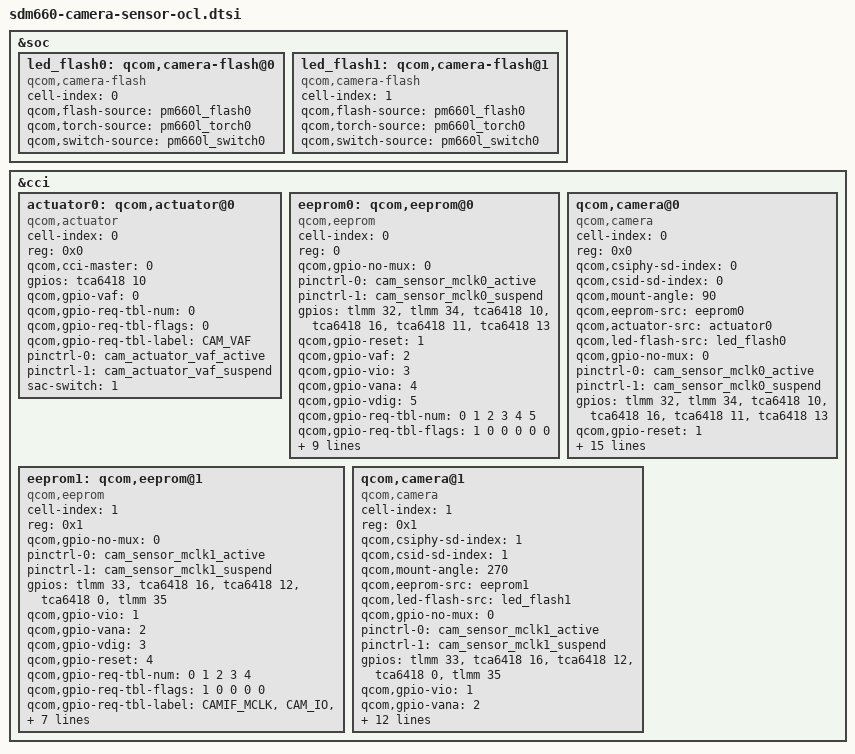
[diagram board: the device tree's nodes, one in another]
/*
 * Copyright (c) 2014, The Linux Foundation. All rights reserved.
 *
 * This program is free software; you can redistribute it and/or modify
 * it under the terms of the GNU General Public License version 2 and
 * only version 2 as published by the Free Software Foundation.
 *
 * This program is distributed in the hope that it will be useful,
 * but WITHOUT ANY WARRANTY; without even the implied warranty of
 * MERCHANTABILITY or FITNESS FOR A PARTICULAR PURPOSE.  See the
 * GNU General Public License for more details.
 */

&soc {
	led_flash0: qcom,camera-flash@0 {
		cell-index = <0>;
		compatible = "qcom,camera-flash";
		qcom,flash-source = <&pm660l_flash0>;
		qcom,torch-source = <&pm660l_torch0>;
		qcom,switch-source = <&pm660l_switch0>;
		status = "ok";
	};
	led_flash1: qcom,camera-flash@1 {
		cell-index = <1>;
		compatible = "qcom,camera-flash";
		qcom,flash-source = <&pm660l_flash0>;
		qcom,torch-source = <&pm660l_torch0>;
		qcom,switch-source = <&pm660l_switch0>;
		status = "ok";
	};
};

&cci {
	actuator0: qcom,actuator@0 {
		cell-index = <0>;
		reg = <0x0>;
		compatible = "qcom,actuator";
		qcom,cci-master = <0>;
		gpios = <&tca6418 10 0>;
		qcom,gpio-vaf = <0>;
		qcom,gpio-req-tbl-num = <0>;
		qcom,gpio-req-tbl-flags = <0>;
		qcom,gpio-req-tbl-label = "CAM_VAF";
		pinctrl-names = "cam_default", "cam_suspend";
		pinctrl-0 = <&cam_actuator_vaf_active>;
		pinctrl-1 = <&cam_actuator_vaf_suspend>;
		sac-switch = <1>;
	};

	eeprom0: qcom,eeprom@0 {
		cell-index = <0>;
		reg = <0>;
		compatible = "qcom,eeprom";
		qcom,gpio-no-mux = <0>;
		pinctrl-names = "cam_default", "cam_suspend";
		pinctrl-0 = <&cam_sensor_mclk0_active>;
		pinctrl-1 = <&cam_sensor_mclk0_suspend>;
		gpios = <&tlmm 32 0>,
			    <&tlmm 34 0>,
			    <&tca6418 10 0>,
			    <&tca6418 16 0>,
			    <&tca6418 11 0>,
			    <&tca6418 13 0>;
		qcom,gpio-reset = <1>;
		qcom,gpio-vaf = <2>;
		qcom,gpio-vio = <3>;
		qcom,gpio-vana = <4>;
		qcom,gpio-vdig = <5>;
		qcom,gpio-req-tbl-num = <0 1 2 3 4 5>;
		qcom,gpio-req-tbl-flags = <1 0 0 0 0 0>;
		qcom,gpio-req-tbl-label = "CAMIF_MCLK0",
					              "CAM_RESET0",
					              "CAM1_VCM2V8_EN",
					              "V_CAMIO_1V8",
					              "CAM1_A2V85_EN",
					              "V_CAM1_D1V2";
		qcom,sensor-position = <0>;
		qcom,sensor-mode = <0>;
		qcom,cci-master = <0>;
		status = "ok";
		clocks = <&clock_mmss MCLK0_CLK_SRC>,<&clock_mmss MMSS_CAMSS_MCLK0_CLK>;
		clock-names = "cam_src_clk", "cam_clk";
		qcom,clock-rates = <24000000 0>;
	};
	eeprom1: qcom,eeprom@1 {
		cell-index = <1>;
		reg = <0x1>;
		compatible = "qcom,eeprom";
		qcom,gpio-no-mux = <0>;
		pinctrl-names = "cam_default", "cam_suspend";
		pinctrl-0 = <&cam_sensor_mclk1_active>;
		pinctrl-1 = <&cam_sensor_mclk1_suspend>;
		gpios = <&tlmm 33 0>,
			    <&tca6418 16 0>,
			    <&tca6418 12 0>,
			    <&tca6418 0 0>,
			    <&tlmm 35 0>;
		qcom,gpio-vio = <1>;
		qcom,gpio-vana = <2>;
		qcom,gpio-vdig = <3>;
		qcom,gpio-reset = <4>;
		qcom,gpio-req-tbl-num = <0 1 2 3 4 >;
		qcom,gpio-req-tbl-flags = <1 0 0 0 0 >;
		qcom,gpio-req-tbl-label = "CAMIF_MCLK",
						"CAM_IO",
						"CAM2_A2V85_EN",
						"CAM2_D1V2",
						"FCAM_PWDN";
		qcom,sensor-position = <1>;
		qcom,sensor-mode = <1>;
		qcom,cci-master = <1>;
		clocks = <&clock_mmss MCLK1_CLK_SRC>,
		<&clock_mmss MMSS_CAMSS_MCLK1_CLK>;
		clock-names = "cam_src_clk", "cam_clk";
		qcom,clock-rates = <24000000 0>;
	};

	qcom,camera@0 {
		cell-index = <0>;
		compatible = "qcom,camera";
		reg = <0x0>;
		qcom,csiphy-sd-index = <0>;
		qcom,csid-sd-index = <0>;
		qcom,mount-angle = <90>;
		qcom,eeprom-src = <&eeprom0>;
		qcom,actuator-src = <&actuator0>;
		qcom,led-flash-src = <&led_flash0>;
		qcom,gpio-no-mux = <0>;
		pinctrl-names = "cam_default", "cam_suspend";
		pinctrl-0 = <&cam_sensor_mclk0_active>;
		pinctrl-1 = <&cam_sensor_mclk0_suspend>;
		gpios = <&tlmm 32 0>,
			    <&tlmm 34 0>,
			    <&tca6418 10 0>,
			    <&tca6418 16 0>,
			    <&tca6418 11 0>,
			    <&tca6418 13 0>;
		qcom,gpio-reset = <1>;
		qcom,gpio-vaf = <2>;
		qcom,gpio-vio = <3>;
		qcom,gpio-vana = <4>;
		qcom,gpio-vdig = <5>;
		qcom,gpio-req-tbl-num = <0 1 2 3 4 5>;
		qcom,gpio-req-tbl-flags = <1 0 0 0 0 0>;
		qcom,gpio-req-tbl-label = "CAMIF_MCLK0",
					              "CAM_RESET0",
					              "CAM1_VCM2V8_EN",
					              "V_CAMIO_1V8",
					              "CAM1_A2V85_EN",
					              "V_CAM1_D1V2";
		qcom,sensor-position = <0>;
		qcom,sensor-mode = <0>;
		qcom,cci-master = <0>;
		status = "ok";
		clocks = <&clock_mmss MCLK0_CLK_SRC>,<&clock_mmss MMSS_CAMSS_MCLK0_CLK>;
		clock-names = "cam_src_clk", "cam_clk";
		qcom,clock-rates = <24000000 0>;
	};
	qcom,camera@1 {
		cell-index = <1>;
		compatible = "qcom,camera";
		reg = <0x1>;
		qcom,csiphy-sd-index = <1>;
		qcom,csid-sd-index = <1>;
		qcom,mount-angle = <270>;
		qcom,eeprom-src = <&eeprom1>;
		qcom,led-flash-src = <&led_flash1>;
		/*
		cam_vdig-supply = <&pm8994_l11>;
		cam_vio-supply = <&pm8994_l14>;
		qcom,cam-vreg-name = "cam_vdig", "cam_vio";
		qcom,cam-vreg-type = <0 0>;
		qcom,cam-vreg-min-voltage = <1050000 1800000>;
		qcom,cam-vreg-max-voltage = <1050000 1800000>;
		qcom,cam-vreg-op-mode = <240000 10100>;
		*/
		qcom,gpio-no-mux = <0>;
		pinctrl-names = "cam_default", "cam_suspend";
		pinctrl-0 = <&cam_sensor_mclk1_active>;
		pinctrl-1 = <&cam_sensor_mclk1_suspend>;
		gpios = <&tlmm 33 0>,
			    <&tca6418 16 0>,
			    <&tca6418 12 0>,
			    <&tca6418 0 0>,
			    <&tlmm 35 0>;
		qcom,gpio-vio = <1>;
		qcom,gpio-vana = <2>;
		qcom,gpio-vdig = <3>;
		qcom,gpio-reset = <4>;
		qcom,gpio-req-tbl-num = <0 1 2 3 4 >;
		qcom,gpio-req-tbl-flags = <1 0 0 0 0 >;
		qcom,gpio-req-tbl-label = "CAMIF_MCLK",
						"CAM_IO",
						"CAM2_A2V85_EN",
						"CAM2_D1V2",
						"FCAM_PWDN";
		qcom,sensor-position = <1>;
		qcom,sensor-mode = <1>;
		qcom,cci-master = <1>;
		status = "ok";
		clocks = <&clock_mmss MCLK1_CLK_SRC>,
				 <&clock_mmss MMSS_CAMSS_MCLK1_CLK>;
		clock-names = "cam_src_clk", "cam_clk";
		qcom,clock-rates = <24000000 0>;
	};
};

